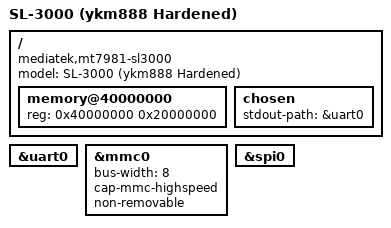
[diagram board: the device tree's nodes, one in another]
/dts-v1/;
#include "mt7981.dtsi"
/ {
  model = "SL-3000 (ykm888 Hardened)";
  compatible = "mediatek,mt7981-sl3000", "mediatek,mt7981";
  memory@40000000 {
    device_type = "memory";
    reg = <0x40000000 0x20000000>;
  };
  chosen { stdout-path = &uart0; };
};
&uart0 { status = "okay"; };
&mmc0 { status = "okay"; bus-width = <8>; cap-mmc-highspeed; non-removable; };
&spi0 { status = "okay"; };
